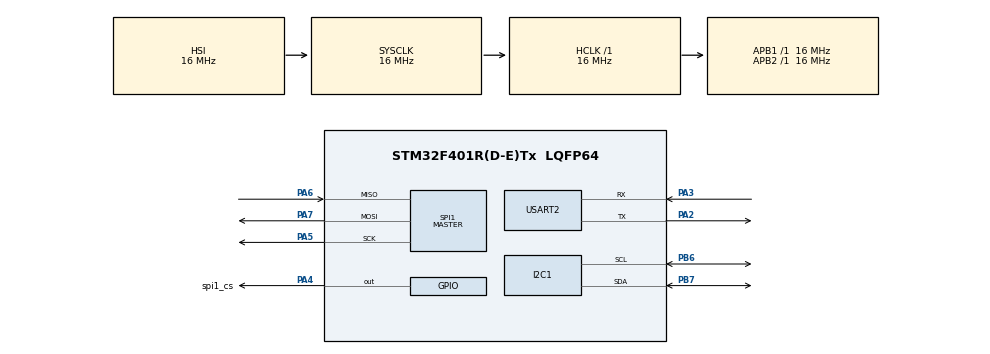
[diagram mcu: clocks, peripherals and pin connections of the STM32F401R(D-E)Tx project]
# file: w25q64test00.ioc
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I2C1.I2C_Mode=I2C_Fast
Mcu.Family=STM32F4
Mcu.Name=STM32F401R(D-E)Tx
Mcu.Package=LQFP64
NVIC.PriorityGroup=NVIC_PRIORITYGROUP_4
NVIC.USART2_IRQn=true\:0\:0\:false\:false\:true\:true\:true\:true
PA2.Mode=Asynchronous
PA2.Signal=USART2_TX
PA3.Mode=Asynchronous
PA3.Signal=USART2_RX
PA4.GPIO_Label=spi1_cs
PA4.Signal=GPIO_Output
PA5.Mode=Full_Duplex_Master
PA5.Signal=SPI1_SCK
PA6.Mode=Full_Duplex_Master
PA6.Signal=SPI1_MISO
PA7.Mode=Full_Duplex_Master
PA7.Signal=SPI1_MOSI
PB6.Mode=I2C
PB6.Signal=I2C1_SCL
PB7.Mode=I2C
PB7.Signal=I2C1_SDA
ProjectManager.HeapSize=0x200
ProjectManager.StackSize=0x400
ProjectManager.TargetToolchain=STM32CubeIDE
RCC.AHBFreq_Value=16000000
RCC.APB1Freq_Value=16000000
RCC.APB2Freq_Value=16000000
RCC.CortexFreq_Value=16000000
RCC.HSE_VALUE=25000000
RCC.HSI_VALUE=16000000
RCC.LSE_VALUE=32768
RCC.SYSCLKFreq_VALUE=16000000
RCC.VCOOutputFreq_Value=192000000
SPI1.Direction=SPI_DIRECTION_2LINES
SPI1.Mode=SPI_MODE_MASTER
SPI1.VirtualType=VM_MASTER
USART2.VirtualMode=VM_ASYNC
board=custom

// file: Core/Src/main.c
/* USER CODE BEGIN Header */
/**
  ******************************************************************************
  * @file           : main.c
  * @brief          : Main program body
  ******************************************************************************
  * @attention
  *
  * Copyright (c) 2022 STMicroelectronics.
  * All rights reserved.
  *
  * This software is licensed under terms that can be found in the LICENSE file
  * in the root directory of this software component.
  * If no LICENSE file comes with this software, it is provided AS-IS.
  *
  ******************************************************************************
  */
/* USER CODE END Header */
#include "main.h"
#include "stdio.h"
#include "string.h"
#include "i2c.h"
#include "spi.h"
#include "usart.h"
#include "gpio.h"
#include "W25QXX.h"

/* USER CODE BEGIN Includes */
uint8_t wData[0x100];
uint8_t rData[0x100];
uint32_t i;
uint8_t ID[2];
/* USER CODE END Includes */

void SystemClock_Config(void);

int main(void)
{

  /* MCU Configuration--------------------------------------------------------*/

  /* Reset of all peripherals, Initializes the Flash interface and the Systick. */
  HAL_Init();

  /* Configure the system clock */
  SystemClock_Config();

  /* Initialize all configured peripherals */
  MX_GPIO_Init();
  MX_I2C1_Init();
  MX_SPI1_Init();
  MX_USART2_UART_Init();

  /* Infinite loop */
  while (1)
  {
	  printf("\r\n SPI-W25Qxxx Example \r\n\r\n");

	    /*##-1- Read the device ID  ########################*/

	    BSP_W25Qx_Init();
	    BSP_W25Qx_Read_ID(ID);

	    printf(" W25Qxxx ID is : 0x%02X 0x%02X \r\n\r\n",ID[0],ID[1]);
	    /*##-2- Erase Block ##################################*/
	    if(BSP_W25Qx_Erase_Block(0) == W25Qx_OK)
	        printf(" SPI Erase Block ok\r\n");
	    else
	        Error_Handler();
	    /*##-3- Written to the flash ########################*/
	    /* fill buffer */
	    for(i =0;i<0x100;i ++)
	    {

	            wData[i] = i;
	          rData[i] = 0;
	    }
	   if(BSP_W25Qx_Write(wData,0x00,0x100)== W25Qx_OK)
	        printf(" SPI Write ok\r\n");
	    else
	        Error_Handler();
	    /*##-4- Read the flash     ########################*/

	    if(BSP_W25Qx_Read(rData,0x00,0x100)== W25Qx_OK)
	        printf(" SPI Read ok\r\n\r\n");
	    else
	        Error_Handler();
	    printf("SPI Read Data : \r\n");
	    for(i =0;i<0x100;i++)
	        printf("0x%02X  ",rData[i]);
	    printf("\r\n\r\n");
	    /*##-5- check date          ########################*/
	    if(memcmp(wData,rData,0x100) == 0 )
	        printf(" W25Q128FV SPI Test OK\r\n");
	    else
	        printf(" W25Q128FV SPI Test False\r\n");

	    HAL_Delay(500);
  }
}

void SystemClock_Config(void)
{
  RCC_OscInitTypeDef RCC_OscInitStruct = {0};
  RCC_ClkInitTypeDef RCC_ClkInitStruct = {0};

  /** Configure the main internal regulator output voltage
  */
  __HAL_RCC_PWR_CLK_ENABLE();
  __HAL_PWR_VOLTAGESCALING_CONFIG(PWR_REGULATOR_VOLTAGE_SCALE2);

  /** Initializes the RCC Oscillators according to the specified parameters
  * in the RCC_OscInitTypeDef structure.
  */
  RCC_OscInitStruct.OscillatorType = RCC_OSCILLATORTYPE_HSI;
  RCC_OscInitStruct.HSIState = RCC_HSI_ON;
  RCC_OscInitStruct.HSICalibrationValue = RCC_HSICALIBRATION_DEFAULT;
  RCC_OscInitStruct.PLL.PLLState = RCC_PLL_NONE;
  if (HAL_RCC_OscConfig(&RCC_OscInitStruct) != HAL_OK)
  {
    Error_Handler();
  }

  /** Initializes the CPU, AHB and APB buses clocks
  */
  RCC_ClkInitStruct.ClockType = RCC_CLOCKTYPE_HCLK|RCC_CLOCKTYPE_SYSCLK
                              |RCC_CLOCKTYPE_PCLK1|RCC_CLOCKTYPE_PCLK2;
  RCC_ClkInitStruct.SYSCLKSource = RCC_SYSCLKSOURCE_HSI;
  RCC_ClkInitStruct.AHBCLKDivider = RCC_SYSCLK_DIV1;
  RCC_ClkInitStruct.APB1CLKDivider = RCC_HCLK_DIV1;
  RCC_ClkInitStruct.APB2CLKDivider = RCC_HCLK_DIV1;

  if (HAL_RCC_ClockConfig(&RCC_ClkInitStruct, FLASH_LATENCY_0) != HAL_OK)
  {
    Error_Handler();
  }
}

void Error_Handler(void)
{
  __disable_irq();
  while (1)
  {
  }
}
